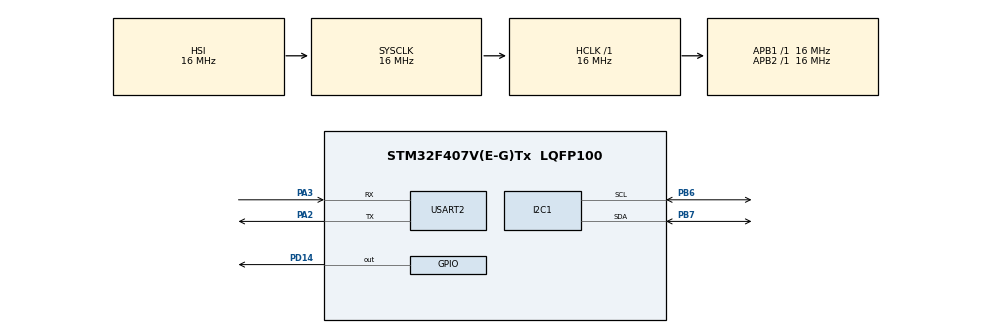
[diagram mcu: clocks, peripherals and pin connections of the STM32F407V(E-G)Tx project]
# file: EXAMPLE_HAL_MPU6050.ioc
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Mcu.Family=STM32F4
Mcu.Name=STM32F407V(E-G)Tx
Mcu.Package=LQFP100
NVIC.PriorityGroup=NVIC_PRIORITYGROUP_4
PA2.Mode=Multiprocessor_communication
PA2.Signal=USART2_TX
PA3.Mode=Multiprocessor_communication
PA3.Signal=USART2_RX
PB6.Mode=I2C
PB6.Signal=I2C1_SCL
PB7.Mode=I2C
PB7.Signal=I2C1_SDA
PD14.Signal=GPIO_Output
ProjectManager.HeapSize=0x200
ProjectManager.StackSize=0x400
ProjectManager.TargetToolchain=STM32CubeIDE
RCC.AHBFreq_Value=16000000
RCC.APB1Freq_Value=16000000
RCC.APB2Freq_Value=16000000
RCC.CortexFreq_Value=16000000
RCC.HSE_VALUE=25000000
RCC.HSI_VALUE=16000000
RCC.LSE_VALUE=32768
RCC.SYSCLKFreq_VALUE=16000000
RCC.VCOOutputFreq_Value=192000000
USART2.VirtualMode=VM_ASYNC
board=custom

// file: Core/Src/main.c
/* USER CODE BEGIN Header */
/**
  ******************************************************************************
  * @file           : main.c
  * @brief          : Main program body
  ******************************************************************************
  * @attention
  *
  * <h2><center>&copy; Copyright (c) 2021 STMicroelectronics.
  * All rights reserved.</center></h2>
  *
  * This software component is licensed by ST under BSD 3-Clause license,
  * the "License"; You may not use this file except in compliance with the
  * License. You may obtain a copy of the License at:
  *                        opensource.org/licenses/BSD-3-Clause
  *
  ******************************************************************************
  */
/* USER CODE END Header */
#include "main.h"

/* USER CODE BEGIN Includes */
#include "TJ_MPU6050.h"
/* USER CODE END Includes */

I2C_HandleTypeDef hi2c1;

UART_HandleTypeDef huart2;

void SystemClock_Config(void);
static void MX_GPIO_Init(void);
static void MX_I2C1_Init(void);
static void MX_USART2_UART_Init(void);

/* USER CODE BEGIN 0 */
RawData_Def myAccelRaw, myGyroRaw;
ScaledData_Def myAccelScaled, myGyroScaled;
/* USER CODE END 0 */

int main(void)
{
  /* USER CODE BEGIN 1 */
	MPU_ConfigTypeDef myMpuConfig;
  /* USER CODE END 1 */

  /* MCU Configuration--------------------------------------------------------*/

  /* Reset of all peripherals, Initializes the Flash interface and the Systick. */
  HAL_Init();

  /* Configure the system clock */
  SystemClock_Config();

  /* Initialize all configured peripherals */
  MX_GPIO_Init();
  MX_I2C1_Init();
  MX_USART2_UART_Init();
  /* USER CODE BEGIN 2 */
  //1. Initialise the MPU6050 module and I2C
  	MPU6050_Init(&hi2c1);
  	//2. Configure Accel and Gyro parameters
  	myMpuConfig.Accel_Full_Scale = AFS_SEL_4g;
  	myMpuConfig.ClockSource = Internal_8MHz;
  	myMpuConfig.CONFIG_DLPF = DLPF_184A_188G_Hz;
  	myMpuConfig.Gyro_Full_Scale = FS_SEL_500;
  	myMpuConfig.Sleep_Mode_Bit = 0;  //1: sleep mode, 0: normal mode
  	MPU6050_Config(&myMpuConfig);
  /* USER CODE END 2 */

  /* Infinite loop */
  while (1)
  {

    /* USER CODE BEGIN 3 */

	  //		//Raw data
	  //		MPU6050_Get_Accel_RawData(&myAccelRaw);
	  //		MPU6050_Get_Gyro_RawData(&myGyroRaw);

	  		//Scaled data
	  MPU6050_Get_Accel_Scale(&myAccelScaled);
	  MPU6050_Get_Gyro_Scale(&myGyroScaled);

	  HAL_GPIO_TogglePin(GPIOD, GPIO_PIN_14);
	  HAL_Delay(10);
  }  /* USER CODE END 3 */
}

void SystemClock_Config(void)
{
  RCC_OscInitTypeDef RCC_OscInitStruct = {0};
  RCC_ClkInitTypeDef RCC_ClkInitStruct = {0};

  /** Configure the main internal regulator output voltage
  */
  __HAL_RCC_PWR_CLK_ENABLE();
  __HAL_PWR_VOLTAGESCALING_CONFIG(PWR_REGULATOR_VOLTAGE_SCALE1);
  /** Initializes the RCC Oscillators according to the specified parameters
  * in the RCC_OscInitTypeDef structure.
  */
  RCC_OscInitStruct.OscillatorType = RCC_OSCILLATORTYPE_HSI;
  RCC_OscInitStruct.HSIState = RCC_HSI_ON;
  RCC_OscInitStruct.HSICalibrationValue = RCC_HSICALIBRATION_DEFAULT;
  RCC_OscInitStruct.PLL.PLLState = RCC_PLL_NONE;
  if (HAL_RCC_OscConfig(&RCC_OscInitStruct) != HAL_OK)
  {
    Error_Handler();
  }
  /** Initializes the CPU, AHB and APB buses clocks
  */
  RCC_ClkInitStruct.ClockType = RCC_CLOCKTYPE_HCLK|RCC_CLOCKTYPE_SYSCLK
                              |RCC_CLOCKTYPE_PCLK1|RCC_CLOCKTYPE_PCLK2;
  RCC_ClkInitStruct.SYSCLKSource = RCC_SYSCLKSOURCE_HSI;
  RCC_ClkInitStruct.AHBCLKDivider = RCC_SYSCLK_DIV1;
  RCC_ClkInitStruct.APB1CLKDivider = RCC_HCLK_DIV1;
  RCC_ClkInitStruct.APB2CLKDivider = RCC_HCLK_DIV1;

  if (HAL_RCC_ClockConfig(&RCC_ClkInitStruct, FLASH_LATENCY_0) != HAL_OK)
  {
    Error_Handler();
  }
}

static void MX_I2C1_Init(void)
{

  hi2c1.Instance = I2C1;
  hi2c1.Init.ClockSpeed = 100000;
  hi2c1.Init.DutyCycle = I2C_DUTYCYCLE_2;
  hi2c1.Init.OwnAddress1 = 0;
  hi2c1.Init.AddressingMode = I2C_ADDRESSINGMODE_7BIT;
  hi2c1.Init.DualAddressMode = I2C_DUALADDRESS_DISABLE;
  hi2c1.Init.OwnAddress2 = 0;
  hi2c1.Init.GeneralCallMode = I2C_GENERALCALL_DISABLE;
  hi2c1.Init.NoStretchMode = I2C_NOSTRETCH_DISABLE;
  if (HAL_I2C_Init(&hi2c1) != HAL_OK)
  {
    Error_Handler();
  }

}

static void MX_USART2_UART_Init(void)
{

  huart2.Instance = USART2;
  huart2.Init.BaudRate = 115200;
  huart2.Init.WordLength = UART_WORDLENGTH_8B;
  huart2.Init.StopBits = UART_STOPBITS_1;
  huart2.Init.Parity = UART_PARITY_NONE;
  huart2.Init.Mode = UART_MODE_TX_RX;
  huart2.Init.HwFlowCtl = UART_HWCONTROL_NONE;
  huart2.Init.OverSampling = UART_OVERSAMPLING_16;
  if (HAL_MultiProcessor_Init(&huart2, 0, UART_WAKEUPMETHOD_IDLELINE) != HAL_OK)
  {
    Error_Handler();
  }

}

static void MX_GPIO_Init(void)
{
  GPIO_InitTypeDef GPIO_InitStruct = {0};

  /* GPIO Ports Clock Enable */
  __HAL_RCC_GPIOA_CLK_ENABLE();
  __HAL_RCC_GPIOD_CLK_ENABLE();
  __HAL_RCC_GPIOB_CLK_ENABLE();

  /*Configure GPIO pin Output Level */
  HAL_GPIO_WritePin(GPIOD, GPIO_PIN_14, GPIO_PIN_RESET);

  /*Configure GPIO pin : PD14 */
  GPIO_InitStruct.Pin = GPIO_PIN_14;
  GPIO_InitStruct.Mode = GPIO_MODE_OUTPUT_PP;
  GPIO_InitStruct.Pull = GPIO_NOPULL;
  GPIO_InitStruct.Speed = GPIO_SPEED_FREQ_LOW;
  HAL_GPIO_Init(GPIOD, &GPIO_InitStruct);

}

void Error_Handler(void)
{
  __disable_irq();
  while (1)
  {
  }
}

/************************ (C) COPYRIGHT STMicroelectronics *****END OF FILE****/
